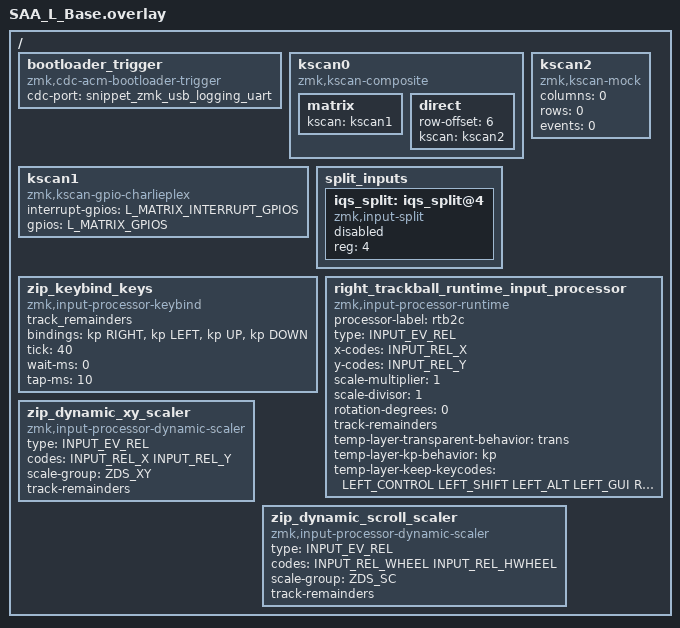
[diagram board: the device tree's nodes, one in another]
#include <input/processors.dtsi>
#include <dt-bindings/zmk/input_transform.h>
#include <dt-bindings/zmk/zip_dynamic_scale.h>
#include <zephyr/dt-bindings/input/input-event-codes.h>
#include <dt-bindings/zmk/keys.h>
#include "SAA.dtsi"
#include <input/processors/runtime-input-processor.dtsi>

/ {
    bootloader_trigger: bootloader_trigger {
        compatible = "zmk,cdc-acm-bootloader-trigger";
        cdc-port = <&snippet_zmk_usb_logging_uart>;
    };

    kscan0: kscan0 {
        compatible = "zmk,kscan-composite";
        matrix {
            kscan = <&kscan1>;
        };
        direct {
            row-offset = <6>;
            kscan = <&kscan2>;
        };
    };

    kscan1: kscan1 {
        compatible = "zmk,kscan-gpio-charlieplex";
        interrupt-gpios = L_MATRIX_INTERRUPT_GPIOS;
        gpios
            = L_MATRIX_GPIOS
            ;
    };

    kscan2: kscan2 {
        compatible = "zmk,kscan-mock";
        columns = <0>;
        rows = <0>;
        events = <0>;
    };
};

/ {
    split_inputs {
        #address-cells = <1>;
        #size-cells = <0>;

        iqs_split: iqs_split@4 {
            compatible = "zmk,input-split";
            status = "disabled";
            reg = <4>;
        };
    };
};

/ {
    zip_keybind_keys: zip_keybind_keys {
        compatible = "zmk,input-processor-keybind";
        #input-processor-cells = <0>;
        track_remainders;
        bindings = <&kp RIGHT>,
                   <&kp LEFT>,
                   <&kp UP>,
                   <&kp DOWN>;
        tick = <40>;
        wait-ms = <0>;
        tap-ms = <10>;
    };

    right_trackball_runtime_input_processor: right_trackball_runtime_input_processor {
        compatible = "zmk,input-processor-runtime";
        processor-label = "rtb2c";
        type = <INPUT_EV_REL>;
        x-codes = <INPUT_REL_X>;
        y-codes = <INPUT_REL_Y>;
        scale-multiplier = <1>;
        scale-divisor = <1>;
        rotation-degrees = <0>;
        track-remainders;

        temp-layer-transparent-behavior = <&trans>;
        temp-layer-kp-behavior = <&kp>;
        temp-layer-keep-keycodes = <LEFT_CONTROL LEFT_SHIFT LEFT_ALT LEFT_GUI RIGHT_CONTROL RIGHT_SHIFT RIGHT_ALT RIGHT_GUI>;

        #input-processor-cells = <0>;
    };

    zip_dynamic_xy_scaler: zip_dynamic_xy_scaler {
        compatible = "zmk,input-processor-dynamic-scaler";
        #input-processor-cells = <0>;
        type = <INPUT_EV_REL>;
        codes = <INPUT_REL_X INPUT_REL_Y>;
        scale-group = <ZDS_XY>;
        track-remainders;
    };

    zip_dynamic_scroll_scaler: zip_dynamic_scroll_scaler {
        compatible = "zmk,input-processor-dynamic-scaler";
        #input-processor-cells = <0>;
        type = <INPUT_EV_REL>;
        codes = <INPUT_REL_WHEEL INPUT_REL_HWHEEL>;
        scale-group = <ZDS_SC>;
        track-remainders;
    };

};
